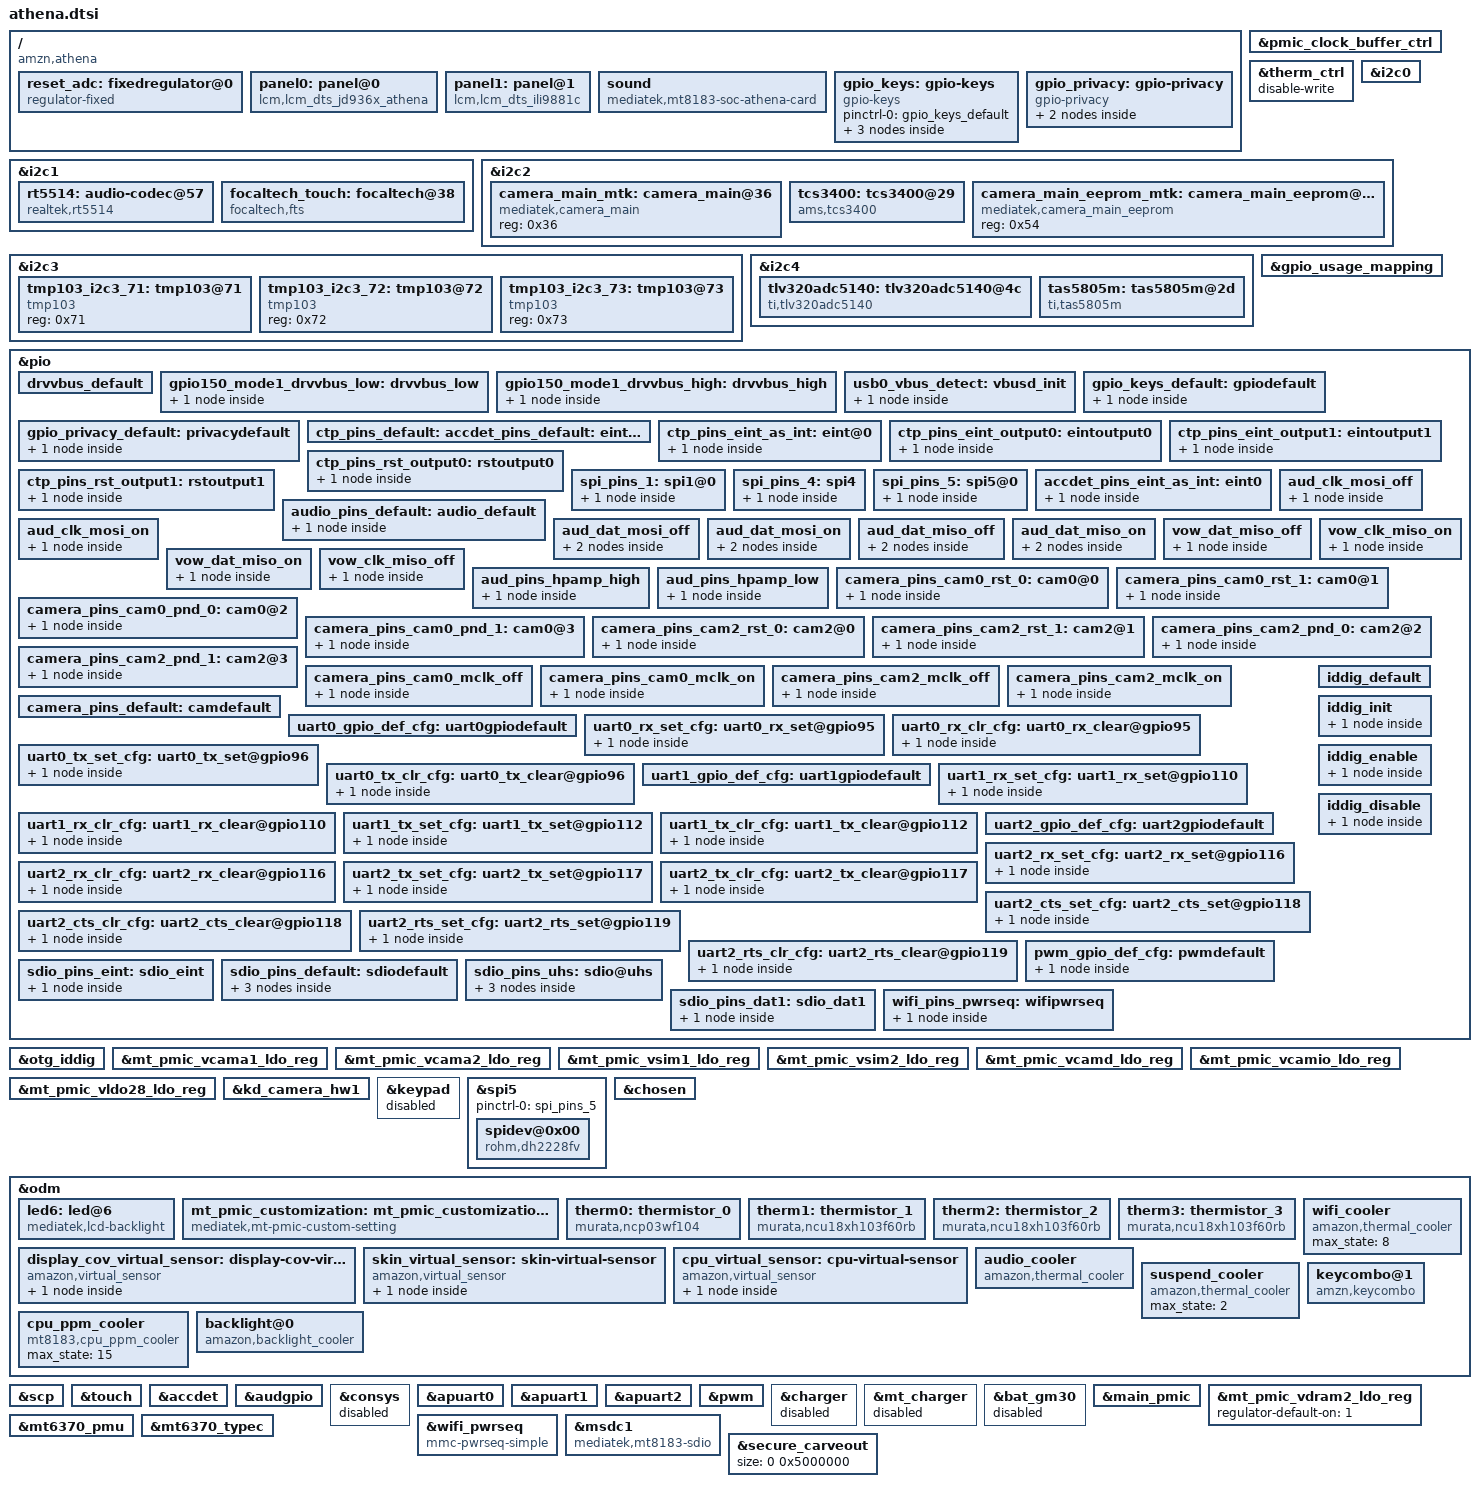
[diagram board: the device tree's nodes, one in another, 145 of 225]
/*
 * Copyright (C) 2020 Amazon.com
 *
 * This program is free software: you can redistribute it and/or modify
 * it under the terms of the GNU General Public License version 2 as
 * published by the Free Software Foundation.
 *
 * This program is distributed in the hope that it will be useful,
 * but WITHOUT ANY WARRANTY; without even the implied warranty of
 * MERCHANTABILITY or FITNESS FOR A PARTICULAR PURPOSE. See the
 * GNU General Public License for more details.
 *
 */

#include "mt8183.dts"
#include <dt-bindings/input/input.h>

/*************************
 * CLK_BUF DTSI File
*************************/

&pmic_clock_buffer_ctrl {
	mediatek,clkbuf-quantity = <7>;
	mediatek,clkbuf-config = <2 1 0 0 0 0 0>;
	mediatek,clkbuf-driving-current = <(-1) (-1) (-1) (-1) (-1) (-1) (-1)>;
	status = "okay";
};

/*************************
 * therm_ctrl DTSI File
*************************/
&therm_ctrl {
	disable-write;
};

/*************************
 * I2C DTSI File
*************************/

&i2c0 {
	#address-cells = <1>;
	#size-cells = <0>;
	clock-frequency = <400000>;
	mediatek,use-open-drain;
};

&i2c1 {
	#address-cells = <1>;
	#size-cells = <0>;
	clock-frequency = <400000>;
	mediatek,use-open-drain;
};

&i2c2 {
	#address-cells = <1>;
	#size-cells = <0>;
	clock-frequency = <400000>;
	mediatek,use-open-drain;
	camera_main_mtk:camera_main@36 {
		compatible = "mediatek,camera_main";
		reg = <0x36>;
		status = "okay";
	};
};

&i2c3 {
	#address-cells = <1>;
	#size-cells = <0>;
	clock-frequency = <400000>;
	mediatek,use-open-drain;
};

&i2c4 {
	#address-cells = <1>;
	#size-cells = <0>;
	clock-frequency = <400000>;
	mediatek,use-open-drain;
};

/*************************
 * GPIO DTSI File
*************************/

&gpio_usage_mapping {
};



/*************************
 * EINT DTSI File
*************************/

#include <dt-bindings/interrupt-controller/irq.h>
#include <dt-bindings/interrupt-controller/arm-gic.h>

&pio {
	drvvbus_default: drvvbus_default {
	};

	gpio150_mode1_drvvbus_low: drvvbus_low {
		pins_cmd_dat {
			pins = <PINMUX_GPIO150__FUNC_GPIO150>;
			slew-rate = <1>;
			output-low;
		};
	};
	gpio150_mode1_drvvbus_high: drvvbus_high {
		pins_cmd_dat {
			pins = <PINMUX_GPIO150__FUNC_GPIO150>;
			slew-rate = <1>;
			output-high;
		};
	};
};
&pio {
	usb0_vbus_detect: vbusd_init {
		pins_cmd_dat {
			pinmux = <PINMUX_GPIO165__FUNC_GPIO165>;
			bias-disable;
		};
	};
};

&otg_iddig {
	interrupt-parent = <&pio>;
	interrupts = <41 IRQ_TYPE_EDGE_FALLING 41 GPIO_ACTIVE_HIGH>;
	pinctrl-names = "iddig_default",
			"iddig_init", "iddig_enable", "iddig_disable",
			"drvvbus_default", "drvvbus_low", "drvvbus_high",
			"vbusd_init";
	pinctrl-0 = <&iddig_default>;
	pinctrl-1 = <&iddig_init>;
	pinctrl-2 = <&iddig_enable>;
	pinctrl-3 = <&iddig_disable>;
	pinctrl-4 = <&drvvbus_default>;
	pinctrl-5 = <&gpio150_mode1_drvvbus_low>;
	pinctrl-6 = <&gpio150_mode1_drvvbus_high>;
	pinctrl-7 = <&usb0_vbus_detect>;
	vbusd,gpio_vbusdetect = <&pio 165 0>;
	vbusd,gpio_pin = <165>;
	vbusd,gpio_edges = <500 1000>;
	vbusd,gpio_polarity = <1>;
	vbusd,gpio_iddig = <&pio 41 0>;
	vbusd,gpio_idpin = <41>;
	status = "okay";
};

/*************************
 * MD1_EINT DTSI File
*************************/



/*************************
 * PMIC DTSI File
*************************/

&mt_pmic_vcama1_ldo_reg {
	regulator-name = "vcama1";
	regulator-default-on = <1>; /* 0:skip, 1: off, 2:on */
	status = "okay";
};
&mt_pmic_vcama2_ldo_reg {
	regulator-name = "vcama2";
	regulator-default-on = <0>; /* 0:skip, 1: off, 2:on */
	status = "okay";
};
&mt_pmic_vsim1_ldo_reg {
	regulator-name = "vsim1";
	regulator-default-on = <2>; /* 0:skip, 1: off, 2:on */
	status = "okay";
};
&mt_pmic_vsim2_ldo_reg {
	regulator-name = "vsim2";
	regulator-default-on = <1>; /* 0:skip, 1: off, 2:on */
	status = "okay";
};
&mt_pmic_vcamd_ldo_reg {
	regulator-name = "vcamd";
	regulator-default-on = <1>; /* 0:skip, 1: off, 2:on */
	status = "okay";
};
&mt_pmic_vcamio_ldo_reg {
	regulator-name = "vcamio";
	regulator-default-on = <1>; /* 0:skip, 1: off, 2:on */
	status = "okay";
};
&mt_pmic_vldo28_ldo_reg {
	regulator-name = "vldo28";
	regulator-default-on = <1>; /* 0:skip, 1: off, 2:on */
	regulator-min-microvolt = <3000000>;
	regulator-max-microvolt = <3000000>;
	status = "okay";
};

&kd_camera_hw1 {
	vcama-supply = <&mt_pmic_vcama1_ldo_reg>;
	vcama_main2-supply = <&mt_pmic_vcama1_ldo_reg>;
	vcamd-supply = <&mt_pmic_vcamd_ldo_reg>;
	vcamd_main2-supply = <&mt_pmic_vcamd_ldo_reg>;
	vcamio-supply = <&mt_pmic_vcamio_ldo_reg>;
	vcamio_main2-supply = <&mt_pmic_vcamio_ldo_reg>;
	vcamaf-supply = <&mt_pmic_vldo28_ldo_reg>;
	vcamaf_main2-supply = <&mt_pmic_vldo28_ldo_reg>;
	status = "okay";
};



/*************************
 * POWER DTSI File
*************************/



/*************************
 * KPD DTSI File
*************************/

&keypad {
	status = "disabled";
};


/**************************
 * athena proto dts
**************************/
/ {
	compatible = "amzn,athena";

	reset_adc: fixedregulator@0 {
		compatible = "regulator-fixed";
		regulator-name = "reset_adc";
		gpio = <&pio 166 GPIO_ACTIVE_HIGH>;
		startup-delay-us = <10000>;
		enable-active-high;
		status = "okay";
	};

	panel0: panel@0 {
		compatible = "lcm,lcm_dts_jd936x_athena";
		pinctrl-names = "default";
		lcm_reset_gpio = <&pio 45 GPIO_ACTIVE_HIGH>;
		lcm_power_p_gpio = <&pio 176 GPIO_ACTIVE_HIGH>;
		lcm_power_n_gpio = <&pio 175 GPIO_ACTIVE_HIGH>;
		lcm-vio-supply = <&mt_pmic_vcama2_ldo_reg>;
		status = "okay";
	};

	panel1: panel@1 {
		compatible = "lcm,lcm_dts_ili9881c";
		pinctrl-names = "default";
		lcm_reset_gpio = <&pio 45 GPIO_ACTIVE_HIGH>;
		lcm_power_p_gpio = <&pio 176 GPIO_ACTIVE_HIGH>;
		lcm_power_n_gpio = <&pio 175 GPIO_ACTIVE_HIGH>;
		lcm-vio-supply = <&mt_pmic_vcama2_ldo_reg>;
		status = "okay";
	};
	sound: sound {
		compatible = "mediatek,mt8183-soc-athena-card";
		/* 0:Stereo, 1:MonoLeft, 2:MonoRight */
		channel-type = <0>;
		switch-mode-delay = <1>;
		/* MCLK Frequency for ADC/DAC */
		mclk-frequency = <24576000>;
		/* enable mic callback for gating mode */
		gating_mode_callback_en = <1>;
		/* enable mclk source for DAC clock, 0 for Bclk */
		use_mclk_source_en = <0>;
		mediatek,audio-always-i2s1-clk-on = <1>;  /* 1: i2s1 clk always on 0: i2s1 clk always off  */
		mediatek,audio-always-i2s2-clk-on = <1>;  /* 1: i2s2 clk always on 0: i2s2 clk always off  */
		mediatek,audio-i2s1-bit-width = <0>; /* 1: 32bit 0: 16bit  */
		mediatek,audio-i2s2-bit-width = <1>; /* 1: 32bit 0: 16bit  */
		mediatek,audio-i2s1-samplerate = <96000>; /* I2S1 samplerate */
		mediatek,audio-i2s2-samplerate = <96000>; /* I2S2 samplerate */
	};

	gpio_keys: gpio-keys {
		status = "okay";
		compatible = "gpio-keys";
		#address-cells = <1>;
		#size-cells = <0>;
		pinctrl-names = "default";
		pinctrl-0 = <&gpio_keys_default>;

		volumeup_button: button@0 {
			debounce_interval = <50>;
			wakeup-source;
			gpios = <&pio 93 GPIO_ACTIVE_LOW>;
			label = "volumeup";
			linux,input-type = <EV_KEY>;
			linux,code = <KEY_VOLUMEUP>;
		};

		volumedown_button: button@1 {
			debounce_interval = <50>;
			wakeup-source;
			gpios = <&pio 92 GPIO_ACTIVE_LOW>;
			label = "volumedown";
			linux,input-type = <EV_KEY>;
			linux,code = <KEY_VOLUMEDOWN>;
		};

		camera_lens_cover {
			label = "Camera Lens Cover";
			debounce-interval = <50>;
			gpios = <&pio 152 GPIO_ACTIVE_LOW>;
			linux,input-type = <EV_SW>;
			linux,code = <SW_CAMERA_LENS_COVER>;
		};
	};

	/* Based on Silego SLG46R43476/SLG46R43993 Mute Privacy */
	gpio_privacy: gpio-privacy {
		compatible = "gpio-privacy";
		status="okay";
		pinctrl-names = "default";
		pinctrl-0 = <&gpio_privacy_default>;

		/* MUTE_SET - output from SoC - 1=software go into muted state, 0=not muted */
		enable-gpio = <&pio 159 GPIO_ACTIVE_HIGH>;
		enable-gpio-toggle-duration = <1000>; /* assert MUTE_SET for 1 second */
		auto-toggle-enable-gpio-time = <50>; /* assert MUTE_SET 50 ms after button release */

		/* privacy event turns into power event after 3 seconds */
		privacy-event-max-press-duration = <3000>;

		state_event {
			label = "mute state";
			linux,input-type = <EV_SW>;
			linux,code = <SW_MUTE_DEVICE>;

			/* MUTE_STATUS_OD_L - input to SoC - 0=muted, 1=not muted */
			gpios = <&pio 63 GPIO_ACTIVE_LOW>;
		};

		button_event {
			label = "power button";
			linux,input-type = <EV_KEY>;
			linux,code = <KEY_POWER>;
			debounce-interval = <50>;
			wakeup-source;

			/* MUTE_BTN_OD_L - input to SoC - 0=button press, 1=button release*/
			gpios = <&pio 168 GPIO_ACTIVE_LOW>;
		};
	};
};

&pio {
	gpio_keys_default: gpiodefault {
		pins_cmd_dat_low {
			pinmux = <PINMUX_GPIO91__FUNC_GPIO91>,
			<PINMUX_GPIO92__FUNC_GPIO92>;
			input-enable;
			slew-rate = <0>;
			bias-pull-up = <MTK_PUPD_SET_R1R0_01>;
		};
	};
	gpio_privacy_default: privacydefault {
		pins_privacydefault {
			pinmux = <PINMUX_GPIO63__FUNC_MIPI0_SDATA>,
			<PINMUX_GPIO168__FUNC_RFIC0_BSI_CK>;
			bias-disable;
		};
	};
};

&spi5 {
	pinctrl-names = "default";
	pinctrl-0 = <&spi_pins_5>;
	status = "okay";

	spidev@0x00 {
		compatible = "rohm,dh2228fv";
		spi-max-frequency = <1200000>;
		reg = <0>;
	};
};

/* chosen */
&chosen {
	bootargs = "console=tty0 console=ttyS0,921600n1 vmalloc=496M slub_max_order=0 slub_debug=OFZPU androidboot.hardware=mt8183 firmware_class.path=/vendor/firmware loop.max_part=7";
};

&odm {
	led6:led@6 {
		compatible = "mediatek,lcd-backlight";
		led_mode = <5>;
		data = <1>;
		pwm_config = <0 0 0 0 0>;
		gpios = <&pio 43 GPIO_ACTIVE_HIGH>;
		linux,default-trigger = "default-on";
		custom-brightness-table = <2 1 0
					249 4 (-8)
					255 6 (-507)>;
	};
	mt_pmic_customization: mt_pmic_customization@0 {
		compatible = "mediatek,mt-pmic-custom-setting";
		custom-reg = <0x1c32 0x1 0x7 0x0 /* LDO_VRF12_OP_EN */
			      0x18ba 0x1 0x1 0x0 /* RG_VPA_NDIS_EN */
			      0x1eae 0xa 0xf 0x0 /* RG_VCAMD_VOCAL */
			      0x1e3c 0xa 0xf 0x0 /* RG_VLDO28_VOCAL */
			      0x014c 0x2 0x3 0xc /* RG_PWRKET_RST_TD */
		>;
		disable-modem = <1>;
	};

	/* Thermistors */
	therm0: thermistor_0 {
		compatible = "murata,ncp03wf104";
		#thermal-sensor-cells = <0>;
		pullup-uv = <1800000>;
		pullup-ohm = <100000>;
		pulldown-ohm = <0>;
		io-channels = <&auxadc 1>;
	};

	therm1: thermistor_1 {
		compatible = "murata,ncu18xh103f60rb";
		#thermal-sensor-cells = <0>;
		pullup-uv = <1800000>;
		pullup-ohm = <10000>;
		pulldown-ohm = <0>;
		io-channels = <&auxadc 2>;
	};

	therm2: thermistor_2 {
		compatible = "murata,ncu18xh103f60rb";
		#thermal-sensor-cells = <0>;
		pullup-uv = <1800000>;
		pullup-ohm = <10000>;
		pulldown-ohm = <0>;
		io-channels = <&auxadc 3>;
	};

	therm3: thermistor_3 {
		compatible = "murata,ncu18xh103f60rb";
		#thermal-sensor-cells = <0>;
		pullup-uv = <1800000>;
		pullup-ohm = <10000>;
		pulldown-ohm = <0>;
		io-channels = <&auxadc 4>;
	};

	display_cov_virtual_sensor: display-cov-virtual-sensor {
		compatible = "amazon,virtual_sensor";
		#thermal-sensor-cells = <0>;

		zone-list {
			zone-names = "therm0_s", "therm1_s", "therm2_s", "therm3_s", "mtktscpu";
			therm0_s = <0 22200 43 698 (-40000) 125000>;
			therm1_s = <0 0 0 0 (-40000) 125000>;
			therm2_s = <0 0 0 0 (-40000) 125000>;
			therm3_s = <1 65000 257 24 (-40000) 125000>;
			mtktscpu = <0 0 0 0 0 0>;
		};

	};

	skin_virtual_sensor: skin-virtual-sensor {
		compatible = "amazon,virtual_sensor";
		#thermal-sensor-cells = <0>;

		zone-list {
			zone-names = "therm0_s", "therm1_s", "therm2_s", "therm3_s", "mtktscpu";
			therm0_s = <0 0 0 0 (-40000) 125000>;
			therm1_s = <0 0 0 0 (-40000) 125000>;
			therm2_s = <0 56500 9 140 (-40000) 125000>;
			therm3_s = <0 71000 558 205 (-40000) 125000>;
			mtktscpu = <0 0 0 0 0 0>;
		};
	};

	cpu_virtual_sensor: cpu-virtual-sensor {
		compatible = "amazon,virtual_sensor";
		#thermal-sensor-cells = <0>;

		zone-list {
			zone-names = "therm0_s", "therm1_s", "therm2_s", "therm3_s", "mtktscpu";
			therm0_s = <0 0 0 0 (-40000) 125000>;
			therm1_s = <0 0 0 0 (-40000) 125000>;
			therm2_s = <0 0 0 0 (-40000) 125000>;
			therm3_s = <0 0 0 0 (-40000) 125000>;
			mtktscpu = <0 0 100 1000 0 0>;
		};
	};

	wifi_cooler: wifi_cooler {
		compatible = "amazon,thermal_cooler";
		#cooling-cells = <2>;
		max_state = <8>;
	};

	audio_cooler: audio_cooler {
		compatible = "amazon,thermal_cooler";
		#cooling-cells = <2>;
		max_level = <3>;
		max_state = <8>;
	};

	suspend_cooler: suspend_cooler {
		compatible = "amazon,thermal_cooler";
		#cooling-cells = <2>;
		max_state = <2>;
	};

	cpu_ppm_cooler: cpu_ppm_cooler {
		compatible = "mt8183,cpu_ppm_cooler";
		#cooling-cells = <2>;
		max_state = <15>;
	};

	/* Backlight Cooler */
	backlight@0 {
		compatible = "amazon,backlight_cooler";
		type = "lcd-backlight0";
		state = <0>;
		max_state = <9>;
		level = <255>;
		levels = <200 200 200 160 160 90 90 90 90>;
	};

	keycombo@1 {
		compatible = "amzn,keycombo";
		keys_down = "KEY_POWER";
		keys_down_delay = <10000>;
		keys_down_func = <1>;		/* power off  */
		status = "okay";
	};
};

&scp {
	core_1 = "enable";
	scp_sramSize = <0x00080000>;     /* scp_A_sram_size */
};

/* TOUCH start */
&touch {
	vtouch-supply = <&mt_pmic_vmch_ldo_reg>;
	tpd-resolution = <800 1280>;
	use-tpd-button = <0>;
	tpd-max-touch-num = <5>;
	tpd-filter-enable = <1>;
	tpd-filter-pixel-density = <124>;
	tpd-filter-custom-prameters = <0 0 0 0 0 0 0 0 0 0 0 0>;
	tpd-filter-custom-speed = <0 0 0>;
	pinctrl-names = "default", "state_eint_as_int", "state_eint_output0", "state_eint_output1",
		"state_rst_output0", "state_rst_output1";
	pinctrl-0 = <&ctp_pins_default>;
	pinctrl-1 = <&ctp_pins_eint_as_int>;
	pinctrl-2 = <&ctp_pins_eint_output0>;
	pinctrl-3 = <&ctp_pins_eint_output1>;
	pinctrl-4 = <&ctp_pins_rst_output0>;
	pinctrl-5 = <&ctp_pins_rst_output1>;
	status = "okay";
};

&pio {
	ctp_pins_default: eint0default {
	};
	ctp_pins_eint_as_int: eint@0 {
		pins_cmd_dat {
			pins = <PINMUX_GPIO10__FUNC_GPIO10>;
			slew-rate = <0>;
			bias-disable;
		};
	};
	ctp_pins_eint_output0: eintoutput0 {
		pins_cmd_dat {
			pins = <PINMUX_GPIO10__FUNC_GPIO10>;
			slew-rate = <1>;
			output-low;
		};
	};
	ctp_pins_eint_output1: eintoutput1 {
		pins_cmd_dat {
			pins = <PINMUX_GPIO10__FUNC_GPIO10>;
			slew-rate = <1>;
			output-high;
		};
	};
	ctp_pins_rst_output0: rstoutput0 {
		pins_cmd_dat {
			pins = <PINMUX_GPIO158__FUNC_GPIO158>;
			slew-rate = <1>;
			output-low;
		};
	};
	ctp_pins_rst_output1: rstoutput1 {
		pins_cmd_dat {
			pins = <PINMUX_GPIO158__FUNC_GPIO158>;
			slew-rate = <1>;
			output-high;
		};
	};
	spi_pins_1: spi1@0{
		pins_spi{
			pinmux = <PINMUX_GPIO161__FUNC_SPI1_A_MI>,
				<PINMUX_GPIO162__FUNC_GPIO162>,
				<PINMUX_GPIO163__FUNC_SPI1_A_MO>,
				<PINMUX_GPIO164__FUNC_SPI1_A_CLK>;
			bias-disable;
		};
	};
	spi_pins_4: spi4{
		pins_spi{
			pinmux = <PINMUX_GPIO17__FUNC_SPI4_MI>,
				 <PINMUX_GPIO18__FUNC_SPI4_CSB>,
				 <PINMUX_GPIO19__FUNC_SPI4_MO>,
				 <PINMUX_GPIO20__FUNC_SPI4_CLK>;
			bias-disable;
		};
	};
	spi_pins_5: spi5@0{
		pins_spi{
			pinmux = <PINMUX_GPIO13__FUNC_SPI5_MI>,
				<PINMUX_GPIO14__FUNC_GPIO14>,
				<PINMUX_GPIO15__FUNC_SPI5_MO>,
				<PINMUX_GPIO16__FUNC_SPI5_CLK>;
			bias-disable;
		};
	};
};
/* TOUCH end */

/* accdet start */
&accdet {
	interrupt-parent = <&pio>;
	interrupts = <0 IRQ_TYPE_LEVEL_LOW 0 0>;
	invert = <1>;
	eint-debounce = <256000>;
	accdet-gpio = <&pio 0 0>;
	accdet-plugout-debounce = <1000>;
	pinctrl-names = "default", "state_eint_as_int";
	pinctrl-0 = <&accdet_pins_default>;
	pinctrl-1 = <&accdet_pins_eint_as_int>;
	status = "okay";
};
&pio {
	accdet_pins_default: eint0default {
	};
	accdet_pins_eint_as_int: eint0 {
		pins_cmd_dat {
			pins = <PINMUX_GPIO0__FUNC_GPIO0>;
			bias-disable;
		};
	};
};
/* accdet end */

/* AUDIO GPIO standardization */
&audgpio {
	pinctrl-names = "default",
			"aud_clk_mosi_off",
			"aud_clk_mosi_on",
			"aud_dat_mosi_off",
			"aud_dat_mosi_on",
			"aud_dat_miso_off",
			"aud_dat_miso_on",
			"vow_dat_miso_off",
			"vow_dat_miso_on",
			"vow_clk_miso_off",
			"vow_clk_miso_on",
			"hpamp-pullhigh",
			"hpamp-pulllow";
	pinctrl-0 = <&audio_pins_default>;
	pinctrl-1 = <&aud_clk_mosi_off>;
	pinctrl-2 = <&aud_clk_mosi_on>;
	pinctrl-3 = <&aud_dat_mosi_off>;
	pinctrl-4 = <&aud_dat_mosi_on>;
	pinctrl-5 = <&aud_dat_miso_off>;
	pinctrl-6 = <&aud_dat_miso_on>;
	pinctrl-7 = <&vow_dat_miso_off>;
	pinctrl-8 = <&vow_dat_miso_on>;
	pinctrl-9 = <&vow_clk_miso_off>;
	pinctrl-10 = <&vow_clk_miso_on>;
	pinctrl-11 = <&aud_pins_hpamp_high>;
	pinctrl-12 = <&aud_pins_hpamp_low>;
	status = "okay";
};

&pio {
	audio_pins_default: audio_default{
		pins_cmd0_dat {
			pins = <PINMUX_GPIO3__FUNC_I2S3_DO>,
				<PINMUX_GPIO5__FUNC_I2S0_BCK>,
				<PINMUX_GPIO6__FUNC_I2S0_LRCK>,
				<PINMUX_GPIO7__FUNC_I2S0_DI>,
				<PINMUX_GPIO170__FUNC_I2S1_BCK>,
				<PINMUX_GPIO171__FUNC_I2S1_LRCK>,
				<PINMUX_GPIO172__FUNC_I2S1_DO>,
				<PINMUX_GPIO173__FUNC_I2S1_MCK>,
				<PINMUX_GPIO12__FUNC_I2S2_DI2>,
				<PINMUX_GPIO98__FUNC_I2S2_BCK>,
				<PINMUX_GPIO101__FUNC_I2S2_LRCK>,
				<PINMUX_GPIO174__FUNC_I2S2_DI>;
		};
	};

	aud_clk_mosi_off: aud_clk_mosi_off {
		pins_cmd0_dat {
			pins = <PINMUX_GPIO136__FUNC_GPIO136>;
		};
	};

	aud_clk_mosi_on: aud_clk_mosi_on {
		pins_cmd0_dat {
			pins = <PINMUX_GPIO136__FUNC_AUD_CLK_MOSI>;
		};
	};

	aud_dat_mosi_off: aud_dat_mosi_off {
		pins_cmd1_dat {
			pins = <PINMUX_GPIO138__FUNC_GPIO138>;
		};
		pins_cmd2_dat {
			pins = <PINMUX_GPIO139__FUNC_GPIO139>;
		};
	};

	aud_dat_mosi_on: aud_dat_mosi_on {
		pins_cmd1_dat {
			pins = <PINMUX_GPIO138__FUNC_AUD_DAT_MOSI0>;
		};
		pins_cmd2_dat {
			pins = <PINMUX_GPIO139__FUNC_AUD_DAT_MOSI1>;
		};
	};

	aud_dat_miso_off: aud_dat_miso_off {
		pins_cmd1_dat {
			pins = <PINMUX_GPIO142__FUNC_GPIO142>;
		};
		pins_cmd2_dat {
			pins = <PINMUX_GPIO143__FUNC_GPIO143>;
		};
	};

	aud_dat_miso_on: aud_dat_miso_on {
		pins_cmd1_dat {
			pins = <PINMUX_GPIO142__FUNC_AUD_DAT_MISO0>;
		};
		pins_cmd2_dat {
			pins = <PINMUX_GPIO143__FUNC_AUD_DAT_MISO1>;
		};
	};

	vow_dat_miso_off: vow_dat_miso_off {
		pins_cmd1_dat {
			pins = <PINMUX_GPIO142__FUNC_GPIO142>;
		};
	};

	vow_dat_miso_on: vow_dat_miso_on {
		pins_cmd1_dat {
			pins = <PINMUX_GPIO142__FUNC_VOW_DAT_MISO>;
		};
	};

	vow_clk_miso_off: vow_clk_miso_off {
		pins_cmd3_dat {
			pins = <PINMUX_GPIO143__FUNC_GPIO143>;
		};
	};

	vow_clk_miso_on: vow_clk_miso_on {
		pins_cmd3_dat {
			pins = <PINMUX_GPIO143__FUNC_VOW_CLK_MISO>;
		};
	};
	aud_pins_hpamp_high: aud_pins_hpamp_high {
		pins_cmd_dat {
			pins = <PINMUX_GPIO35__FUNC_GPIO35>;
			slew-rate = <1>;
			output-high;
		};
	};

	aud_pins_hpamp_low: aud_pins_hpamp_low {
		pins_cmd_dat {
			pins = <PINMUX_GPIO35__FUNC_GPIO35>;
			slew-rate = <1>;
			output-low;
		};
	};

};

/* AUDIO end */

&consys {
	status = "disabled";
};

/* CAMERA GPIO standardization */
&pio {
	camera_pins_cam0_rst_0: cam0@0 {
		pins_cmd_dat {
			pins = <PINMUX_GPIO102__FUNC_GPIO102>;
			output-low;
		};
	};
	camera_pins_cam0_rst_1: cam0@1 {
		pins_cmd_dat {
			pins = <PINMUX_GPIO102__FUNC_GPIO102>;
			output-high;
		};
	};
	camera_pins_cam0_pnd_0: cam0@2 {
		pins_cmd_dat {
			pins = <PINMUX_GPIO177__FUNC_GPIO177>;
			output-low;
		};
	};
	camera_pins_cam0_pnd_1: cam0@3 {
		pins_cmd_dat {
			pins = <PINMUX_GPIO177__FUNC_GPIO177>;
			output-high;
		};
	};
	camera_pins_cam2_rst_0: cam2@0 {
		pins_cmd_dat {
			pins = <PINMUX_GPIO102__FUNC_GPIO102>;
			output-low;
		};
	};
	camera_pins_cam2_rst_1: cam2@1 {
		pins_cmd_dat {
			pins = <PINMUX_GPIO102__FUNC_GPIO102>;
			output-high;
		};
	};
	camera_pins_cam2_pnd_0: cam2@2 {
		pins_cmd_dat {
			pins = <PINMUX_GPIO177__FUNC_GPIO177>;
			output-low;
		};
	};
	camera_pins_cam2_pnd_1: cam2@3 {
		pins_cmd_dat {
			pins = <PINMUX_GPIO177__FUNC_GPIO177>;
			output-high;
		};
	};
	camera_pins_cam0_mclk_off: camera_pins_cam0_mclk_off {
		pins_cmd_dat {
			pins = <PINMUX_GPIO99__FUNC_GPIO99>;
		};
	};
	camera_pins_cam0_mclk_on: camera_pins_cam0_mclk_on {
		pins_cmd_dat {
			pins = <PINMUX_GPIO99__FUNC_CMMCLK0>;
		};
	};
	camera_pins_cam2_mclk_off: camera_pins_cam2_mclk_off {
		pins_cmd_dat {
			pins = <PINMUX_GPIO99__FUNC_GPIO99>;
		};
	};
	camera_pins_cam2_mclk_on: camera_pins_cam2_mclk_on {
		pins_cmd_dat {
			pins = <PINMUX_GPIO99__FUNC_CMMCLK0>;
		};
	};

	camera_pins_default: camdefault {
	};
};
&kd_camera_hw1 {
	pinctrl-names = "default",
			"cam0_rst0", "cam0_rst1",
			"cam0_pnd0", "cam0_pnd1",
			"cam2_rst0", "cam2_rst1",
			"cam2_pnd0", "cam2_pnd1",
			"cam0_mclk_off", "cam0_mclk_on",
			"cam2_mclk_off", "cam2_mclk_on";
	pinctrl-0 = <&camera_pins_default>;
	pinctrl-1 = <&camera_pins_cam0_rst_0>;
	pinctrl-2 = <&camera_pins_cam0_rst_1>;
	pinctrl-3 = <&camera_pins_cam0_pnd_0>;
	pinctrl-4 = <&camera_pins_cam0_pnd_1>;
	pinctrl-5 = <&camera_pins_cam2_rst_0>;
	pinctrl-6 = <&camera_pins_cam2_rst_1>;
	pinctrl-7 = <&camera_pins_cam2_pnd_0>;
	pinctrl-8 = <&camera_pins_cam2_pnd_1>;
	pinctrl-9 = <&camera_pins_cam0_mclk_off>;
	pinctrl-10 = <&camera_pins_cam0_mclk_on>;
	pinctrl-11 = <&camera_pins_cam2_mclk_off>;
	pinctrl-12 = <&camera_pins_cam2_mclk_on>;
	status = "okay";
};
/* CAMERA GPIO end */


&mt_pmic_vcamio_ldo_reg {
	regulator-name = "vcamio";
	regulator-min-microvolt = <1800000>;
	regulator-max-microvolt = <1800000>;
	regulator-enable-ramp-delay = <270>;
	status = "okay";
};
&mt_pmic_vcamd_ldo_reg {
	regulator-name = "vcamd";
	regulator-min-microvolt = <1200000>;
	regulator-max-microvolt = <1200000>;
	regulator-enable-ramp-delay = <270>;
	status = "okay";
};

&mt_pmic_vcama1_ldo_reg {
	regulator-name = "vcama1";
	regulator-min-microvolt = <2800000>;
	regulator-max-microvolt = <2800000>;
	status = "okay";
};
&mt_pmic_vcama2_ldo_reg {
	regulator-name = "vcama2";
	regulator-min-microvolt = <1800000>;
	regulator-max-microvolt = <1800000>;
	status = "okay";
};

/* UART GPIO */
&apuart0 {
	pinctrl-names = "uart0_gpio_default",
			"uart0_rx_set",
			"uart0_rx_clear",
			"uart0_tx_set",
			"uart0_tx_clear";
	pinctrl-0 = <&uart0_gpio_def_cfg>;
	pinctrl-1 = <&uart0_rx_set_cfg>;
	pinctrl-2 = <&uart0_rx_clr_cfg>;
	pinctrl-3 = <&uart0_tx_set_cfg>;
	pinctrl-4 = <&uart0_tx_clr_cfg>;
	status = "okay";
};

&apuart1 {
	pinctrl-names = "uart1_gpio_default",
			"uart1_rx_set",
			"uart1_rx_clear",
			"uart1_tx_set",
			"uart1_tx_clear";
	pinctrl-0 = <&uart1_gpio_def_cfg>;
	pinctrl-1 = <&uart1_rx_set_cfg>;
	pinctrl-2 = <&uart1_rx_clr_cfg>;
	pinctrl-3 = <&uart1_tx_set_cfg>;
	pinctrl-4 = <&uart1_tx_clr_cfg>;
	status = "okay";
};

&apuart2 {
	pinctrl-names = "uart2_gpio_default",
			"uart2_rx_set",
			"uart2_rx_clear",
			"uart2_tx_set",
			"uart2_tx_clear",
			"uart2_cts_set",
			"uart2_cts_clear",
			"uart2_rts_set",
			"uart2_rts_clear";
	pinctrl-0 = <&uart2_gpio_def_cfg>;
	pinctrl-1 = <&uart2_rx_set_cfg>;
	pinctrl-2 = <&uart2_rx_clr_cfg>;
	pinctrl-3 = <&uart2_tx_set_cfg>;
	pinctrl-4 = <&uart2_tx_clr_cfg>;
	pinctrl-5 = <&uart2_cts_set_cfg>;
	pinctrl-6 = <&uart2_cts_clr_cfg>;
	pinctrl-7 = <&uart2_rts_set_cfg>;
	pinctrl-8 = <&uart2_rts_clr_cfg>;
	status = "okay";
};

&pio {
	/* UART GPIO Settings - Start */
	/* UART0: rx set, rx clear, tx clear, tx clear*/
	uart0_gpio_def_cfg:uart0gpiodefault {

	};
	uart0_rx_set_cfg:uart0_rx_set@gpio95 {
		pins_cmd_dat {
			pins = <PINMUX_GPIO95__FUNC_URXD0>;
		};
	};
	uart0_rx_clr_cfg:uart0_rx_clear@gpio95 {
		pins_cmd_dat {
			pins = <PINMUX_GPIO95__FUNC_GPIO95>;
			slew-rate = <1>;
			output-high;
		};
	};
	uart0_tx_set_cfg:uart0_tx_set@gpio96 {
		pins_cmd_dat {
			pins = <PINMUX_GPIO96__FUNC_UTXD0>;
		};
	};
	uart0_tx_clr_cfg:uart0_tx_clear@gpio96 {
		pins_cmd_dat {
			pins = <PINMUX_GPIO96__FUNC_GPIO96>;
			slew-rate = <1>;
			output-high;
		};
	};

	/* UART1: rx set, rx clear, tx clear, tx clear*/
	uart1_gpio_def_cfg:uart1gpiodefault {

	};
	uart1_rx_set_cfg:uart1_rx_set@gpio110 {
		pins_cmd_dat {
			pins = <PINMUX_GPIO110__FUNC_URXD1>;
		};
	};
	uart1_rx_clr_cfg:uart1_rx_clear@gpio110 {
		pins_cmd_dat {
			pins = <PINMUX_GPIO110__FUNC_GPIO110>;
			slew-rate = <1>;
			output-high;
		};
	};
	uart1_tx_set_cfg:uart1_tx_set@gpio112 {
		pins_cmd_dat {
			pins = <PINMUX_GPIO112__FUNC_UTXD1>;
		};
	};
	uart1_tx_clr_cfg:uart1_tx_clear@gpio112 {
		pins_cmd_dat {
			pins = <PINMUX_GPIO112__FUNC_GPIO112>;
			slew-rate = <1>;
			output-high;
		};
	};

	/* UART2: rx set, rx clear, tx clear, tx clear*/
	uart2_gpio_def_cfg:uart2gpiodefault {

	};
	uart2_rx_set_cfg:uart2_rx_set@gpio116 {
		pins_cmd_dat {
			pins = <PINMUX_GPIO116__FUNC_TP_URXD2_AO>;
		};
	};
	uart2_rx_clr_cfg:uart2_rx_clear@gpio116 {
		pins_cmd_dat {
			pins = <PINMUX_GPIO116__FUNC_GPIO116>;
			slew-rate = <1>;
			output-high;
		};
	};
	uart2_tx_set_cfg:uart2_tx_set@gpio117 {
		pins_cmd_dat {
			pins = <PINMUX_GPIO117__FUNC_TP_UTXD2_AO>;
		};
	};
	uart2_tx_clr_cfg:uart2_tx_clear@gpio117 {
		pins_cmd_dat {
			pins = <PINMUX_GPIO117__FUNC_GPIO117>;
			slew-rate = <1>;
			output-high;
		};
	};
	uart2_cts_set_cfg:uart2_cts_set@gpio118 {
		pins_cmd_dat {
			pins = <PINMUX_GPIO118__FUNC_TP_UCTS2_AO>;
		};
	};
	uart2_cts_clr_cfg:uart2_cts_clear@gpio118 {
		pins_cmd_dat {
			pins = <PINMUX_GPIO118__FUNC_TP_UCTS2_AO>;
			slew-rate = <1>;
			output-high;
		};
	};
	uart2_rts_set_cfg:uart2_rts_set@gpio119 {
		pins_cmd_dat {
			pins = <PINMUX_GPIO119__FUNC_TP_URTS2_AO>;
		};
	};
	uart2_rts_clr_cfg:uart2_rts_clear@gpio119 {
		pins_cmd_dat {
			pins = <PINMUX_GPIO119__FUNC_TP_URTS2_AO>;
			slew-rate = <1>;
			output-high;
		};
	};
};/* UART GPIO end */

/* PWM GPIO */
&pwm {
	pinctrl-names = "default";
	pinctrl-0 = <&pwm_gpio_def_cfg>;
	pwm_frequency = <5250>;
	status = "okay";
};

&pio {
	pwm_gpio_def_cfg: pwmdefault {
		pins_cmd_dat {
			pinmux = <PINMUX_GPIO153__FUNC_PWM_A>;
		};
	};
};
/* PWM GPIO end */

&charger {
	status = "disabled";
};

&mt_charger {
	status = "disabled";
};

/delete-node/ &lk_charger;

&bat_gm30 {
	status = "disabled";
};

&i2c0 {
	clock-frequency = <400000>;
	status = "okay";
};

&i2c1 {
	clock-frequency = <400000>;
	status = "okay";

	rt5514: audio-codec@57 {
		compatible = "realtek,rt5514";
		#sound-dai-cells = <0>;
		reg = <0x57>;
		interrupt-parent = <&pio>;
		interrupts = <0 IRQ_TYPE_LEVEL_HIGH 0 0>;
	};

	focaltech_touch: focaltech@38 {
		compatible = "focaltech,fts";
		reg = <0x38>;
		vdd-supply = <&mt_pmic_vmch_ldo_reg>;
		interrupt-parent = <&pio>;
		interrupts = <10 IRQ_TYPE_LEVEL_LOW 10 0>;
		focaltech,reset-gpio = <&pio 158 GPIO_ACTIVE_LOW>;
		focaltech,irq-gpio = <&pio 10 GPIO_ACTIVE_LOW>;
		focaltech,max-touch-number = <5>;
		focaltech,display-coords = <0 0 1280 800>; /* resolution */
	};
};

&i2c2 {
	clock-frequency = <400000>;
	status = "okay";

	tcs3400: tcs3400@29 {
		compatible = "ams,tcs3400";
		reg = <0x29>;
		interrupt-parent = <&pio>;
		interrupts = <9 IRQ_TYPE_LEVEL_LOW 9 0>;
		als_name = "tcs3400_als";
		persist = <2>;
		als_gain = <3>;
		als_auto_gain = <1>;
		als_deltap = <10>;
		als_time = <4>;
		als_can_wake = <0>;
	};

	camera_main_eeprom_mtk: camera_main_eeprom@54 {
		compatible = "mediatek,camera_main_eeprom";
		reg = <0x54>;
		status = "okay";
	};
};

&i2c3 {
	clock-frequency = <400000>;
	status = "okay";

	tmp103_i2c3_71: tmp103@71 {
		compatible = "tmp103";
		reg = <0x71>;
	};
	tmp103_i2c3_72: tmp103@72 {
		compatible = "tmp103";
		reg = <0x72>;
	};
	tmp103_i2c3_73: tmp103@73 {
		compatible = "tmp103";
		reg = <0x73>;
	};
};

&i2c4 {
	tlv320adc5140: tlv320adc5140@4c {
		compatible = "ti,tlv320adc5140";
		reg = <0x4c>;
		reset-adc-regulator-supply = <&reset_adc>;
		adc-num = <0>;
		status = "okay";
	};

	tas5805m: tas5805m@2d {
		compatible = "ti,tas5805m";
		reg = <0x2d>;
		vcn33_wifi-supply = <&mt_pmic_vldo28_ldo_reg>;
		vsim2-supply = <&mt_pmic_vrf18_ldo_reg>;
		reset-gpio = <&pio 37 0>;
		speaker-config = <1>;
		swap-channels;
		tweeter-amp-lpm-mode = <1>; /* By default enable lpm mode for Athena */
		status = "okay";
	};
};

&main_pmic {
	interrupt-parent = <&pio>;
	interrupts = <182 IRQ_TYPE_LEVEL_HIGH 190 0>;
	status = "okay";
};

&mt_pmic_vdram2_ldo_reg {
	regulator-default-on = <1>;
};

&mt6370_pmu {
	mt6370,intr_gpio_num = <10>; /* direct defined GPIO num */
	mt6370,intr_gpio = <&pio 10 GPIO_ACTIVE_HIGH>;
};

&mt6370_typec {
	mt6370pd,intr_gpio_num = <41>; /* direct defined GPIO num */
	mt6370pd,intr_gpio = <&pio 41 GPIO_ACTIVE_HIGH>;
};

&wifi_pwrseq {
	compatible = "mmc-pwrseq-simple";
	pinctrl-names = "default";
	pinctrl-0 = <&wifi_pins_pwrseq>;

	/* Toggle WIFI_ENABLE to reset the chip */
	reset-gpios = <&pio 68 1>;
};

&msdc1 {
	compatible = "mediatek,mt8183-sdio";
	reg = <0x0 0x11240000 0x0 0x10000>,
	    <0 0x11e10000 0 0x1000>;
	clocks = <&infracfg_ao INFRACFG_AO_MSDC1_SCK_CG>,
	       <&infracfg_ao INFRACFG_AO_MSDC1_CG>;
	clock-names = "source", "hclk";
	status = "okay";
	eint-gpios = <&pio 34 GPIO_ACTIVE_HIGH>;
	bus-width = <4>;
	max-frequency = <200000000>;
	cap-sd-highspeed;
	sd-uhs-sdr50;
	sd-uhs-sdr104;
	pinctrl-names = "state_eint", "default", "state_uhs", "state_dat1";
	pinctrl-0 = <&sdio_pins_eint>;
	pinctrl-1 = <&sdio_pins_default>;
	pinctrl-2 = <&sdio_pins_uhs>;
	pinctrl-3 = <&sdio_pins_dat1>;
	keep-power-in-suspend;
	enable-sdio-wakeup;
	cap-sdio-irq;
	non-removable;
	vmmc-supply = <&mt_pmic_vmch_ldo_reg>;
	vqmmc-supply = <&mt_pmic_vmc_ldo_reg>;
	mmc-pwrseq = <&wifi_pwrseq>;
};

&pio {
	sdio_pins_eint: sdio_eint {
		pins_dat1 {
			pinmux = <PINMUX_GPIO34__FUNC_GPIO34>;
			drive-strength = <MTK_DRIVE_6mA>;
			bias-pull-up = <MTK_PUPD_SET_R1R0_01>;
			output-high;
		};
	};

	sdio_pins_default: sdiodefault {
		pins_cmd_dat {
			pinmux = <PINMUX_GPIO31__FUNC_MSDC1_CMD>,
			       <PINMUX_GPIO32__FUNC_MSDC1_DAT0>,
			       <PINMUX_GPIO34__FUNC_MSDC1_DAT1>,
			       <PINMUX_GPIO33__FUNC_MSDC1_DAT2>,
			       <PINMUX_GPIO30__FUNC_MSDC1_DAT3>;
			drive-strength = <MTK_DRIVE_6mA>;
			bias-pull-up = <MTK_PUPD_SET_R1R0_01>;
			output-high;
		};

		pins_clk {
			pinmux = <PINMUX_GPIO29__FUNC_MSDC1_CLK>;
			drive-strength = <MTK_DRIVE_6mA>;
			bias-pull-down = <MTK_PUPD_SET_R1R0_10>;
			output-low;
		};

		pins_pmu {
			pinmux = <PINMUX_GPIO160__FUNC_GPIO160>;
			bias-pull-up;
			output-enable;
			output-high;
		};
	};

	sdio_pins_uhs: sdio@uhs {
		pins_cmd_dat {
			pinmux = <PINMUX_GPIO31__FUNC_MSDC1_CMD>,
			       <PINMUX_GPIO32__FUNC_MSDC1_DAT0>,
			       <PINMUX_GPIO34__FUNC_MSDC1_DAT1>,
			       <PINMUX_GPIO33__FUNC_MSDC1_DAT2>,
			       <PINMUX_GPIO30__FUNC_MSDC1_DAT3>;
			drive-strength = <MTK_DRIVE_6mA>;
			bias-pull-up = <MTK_PUPD_SET_R1R0_01>;
			output-high;
		};

		pins_clk {
			pinmux = <PINMUX_GPIO29__FUNC_MSDC1_CLK>;
			drive-strength = <MTK_DRIVE_6mA>;
			bias-pull-down = <MTK_PUPD_SET_R1R0_10>;
			output-low;
		};

		pins_pmu {
			pinmux = <PINMUX_GPIO160__FUNC_GPIO160>;
			bias-pull-up;
			output-enable;
			output-high;
		};
	};

	sdio_pins_dat1: sdio_dat1 {
		pins_dat1 {
			pinmux = <PINMUX_GPIO34__FUNC_MSDC1_DAT1>;
			drive-strength = <MTK_DRIVE_6mA>;
			bias-pull-up = <MTK_PUPD_SET_R1R0_01>;
			output-high;
		};
	};

	wifi_pins_pwrseq: wifipwrseq {
		pins_wifi_enable {
			pinmux = <PINMUX_GPIO68__FUNC_GPIO68>;
			drive-strength = <MTK_DRIVE_8mA>;
			output-low;
		};
	};
};

/* USB Setting -Start */
&pio {
	iddig_default: iddig_default {
	};
	iddig_init: iddig_init {
		pins_cmd_dat {
			pins = <PINMUX_GPIO41__FUNC_IDDIG>;
			input-enable;
			slew-rate = <0>;
			bias-pull-up = <MTK_PUPD_SET_R1R0_01>;
		};
	};
	iddig_enable: iddig_enable {
		pins_cmd_dat {
			pins = <PINMUX_GPIO41__FUNC_IDDIG>;
			input-enable;
			slew-rate = <0>;
			bias-pull-up = <MTK_PUPD_SET_R1R0_01>;
		};
	};
	iddig_disable: iddig_disable {
		pins_cmd_dat {
			pins = <PINMUX_GPIO41__FUNC_GPIO41>;
			input-disable;
			slew-rate = <1>;
			output-low;
		};
	};
};


&secure_carveout {
	size = <0 0x5000000>;
};

#include "athena_thermal_zones.dtsi"
